# HC32F460PCTB register map
File version: 1.0
CPU: CM4 r0p1, little endian, MPU, FPU, 4 interrupt priority bits
Registers are 32-bit, read-write, reset 0x0 unless marked. A register's access mark holds for its fields unless they carry their own. Offsets are from the block's base; [hi:lo] are bit positions; {n}, {i} and the like mark numbered series.

## AES
Base 0x40008000
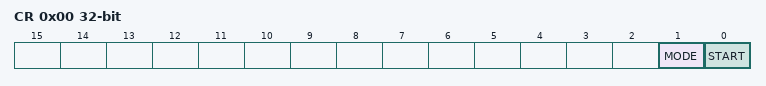
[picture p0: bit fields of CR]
0x00 CR
  [1] MODE, [0] START
{0x10+4i} DR{i} (i=0..3)
{0x20+4i} KR{i} (i=0..3)

## AOS
Base 0x40010800
0x00 INTSFTTRG wo
  [0] STRG
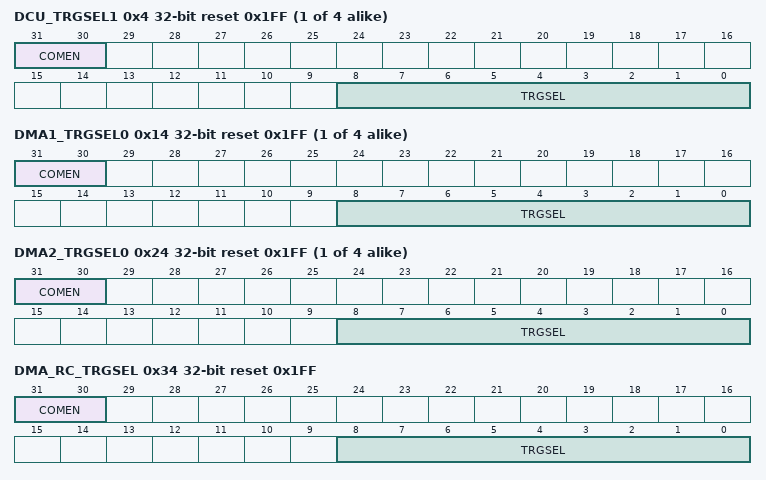
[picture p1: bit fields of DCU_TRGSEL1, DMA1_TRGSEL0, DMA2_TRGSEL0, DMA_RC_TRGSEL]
{0x0+4i} DCU_TRGSEL{i} reset 0x1FF (i=1..4)
  [31:30] COMEN, [8:0] TRGSEL
{0x14+4i} DMA1_TRGSEL{i} reset 0x1FF (i=0..3)
  [31:30] COMEN, [8:0] TRGSEL
{0x24+4i} DMA2_TRGSEL{i} reset 0x1FF (i=0..3)
  [31:30] COMEN, [8:0] TRGSEL
0x34 DMA_RC_TRGSEL reset 0x1FF
  [31:30] COMEN, [8:0] TRGSEL
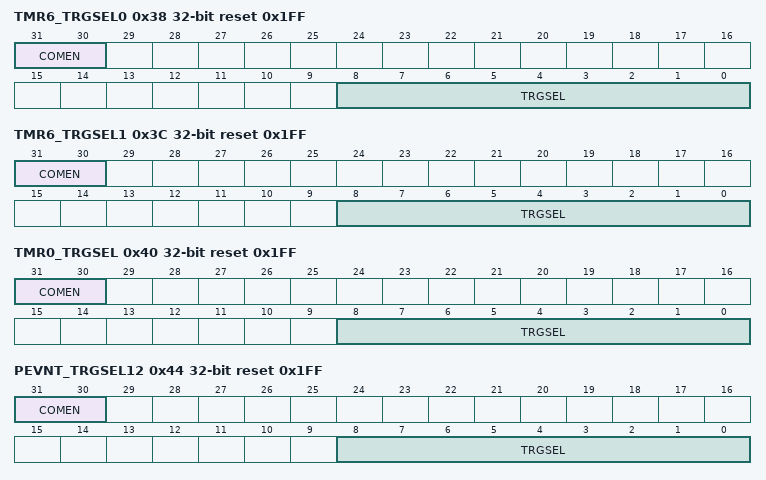
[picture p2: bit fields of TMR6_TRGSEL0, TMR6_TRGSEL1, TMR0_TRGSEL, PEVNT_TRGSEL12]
0x38 TMR6_TRGSEL0 reset 0x1FF
  [31:30] COMEN, [8:0] TRGSEL
0x3C TMR6_TRGSEL1 reset 0x1FF
  [31:30] COMEN, [8:0] TRGSEL
0x40 TMR0_TRGSEL reset 0x1FF
  [31:30] COMEN, [8:0] TRGSEL
0x44 PEVNT_TRGSEL12 reset 0x1FF
  [31:30] COMEN, [8:0] TRGSEL
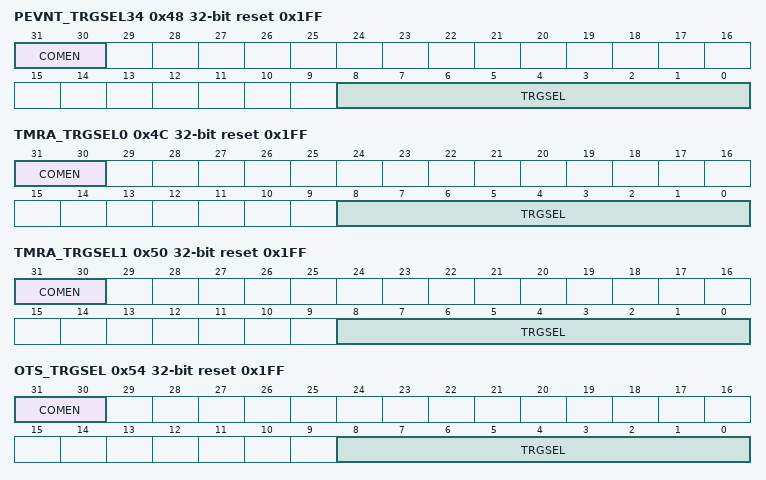
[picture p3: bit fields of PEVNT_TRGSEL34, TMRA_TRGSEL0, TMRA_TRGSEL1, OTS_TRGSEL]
0x48 PEVNT_TRGSEL34 reset 0x1FF
  [31:30] COMEN, [8:0] TRGSEL
0x4C TMRA_TRGSEL0 reset 0x1FF
  [31:30] COMEN, [8:0] TRGSEL
0x50 TMRA_TRGSEL1 reset 0x1FF
  [31:30] COMEN, [8:0] TRGSEL
0x54 OTS_TRGSEL reset 0x1FF
  [31:30] COMEN, [8:0] TRGSEL
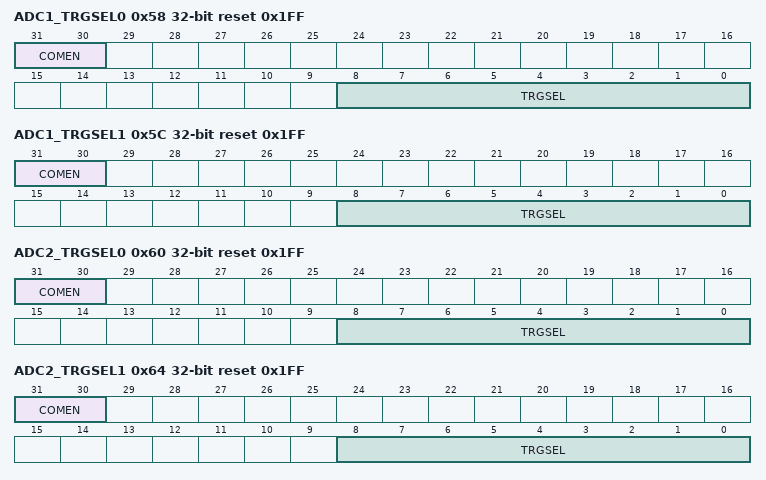
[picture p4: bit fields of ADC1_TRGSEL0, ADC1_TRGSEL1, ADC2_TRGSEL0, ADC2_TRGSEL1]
0x58 ADC1_TRGSEL0 reset 0x1FF
  [31:30] COMEN, [8:0] TRGSEL
0x5C ADC1_TRGSEL1 reset 0x1FF
  [31:30] COMEN, [8:0] TRGSEL
0x60 ADC2_TRGSEL0 reset 0x1FF
  [31:30] COMEN, [8:0] TRGSEL
0x64 ADC2_TRGSEL1 reset 0x1FF
  [31:30] COMEN, [8:0] TRGSEL
0x68 COMTRG1 reset 0x1FF
  [8:0] COMTRG
0x6C COMTRG2 reset 0x1FF
  [8:0] COMTRG
{0xE4+0x1C*i} PEVNTDIRR{i} (i=1..4)
  [15:0] PDIR
{0xE8+0x1C*i} PEVNTIDR{i} ro (i=1..4)
  [15:0] PIN
{0xEC+0x1C*i} PEVNTODR{i} (i=1..4)
  [15:0] POUT
{0xF0+0x1C*i} PEVNTORR{i} (i=1..4)
  [15:0] POR
{0xF4+0x1C*i} PEVNTOSR{i} (i=1..4)
  [15:0] POS
{0xF8+0x1C*i} PEVNTRISR{i} (i=1..4)
  [15:0] RIS
{0xFC+0x1C*i} PEVNTFALR{i} (i=1..4)
  [15:0] FAL
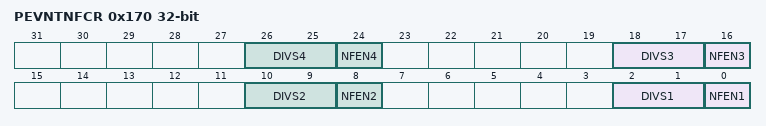
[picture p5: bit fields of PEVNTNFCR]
0x170 PEVNTNFCR
  [8n-6:8n-7] DIVS{n} (n=1..4), [8n-8] NFEN{n} (n=1..4)

## CAN
Base 0x40070400
0x00 RBUF ro
0x50 TBUF
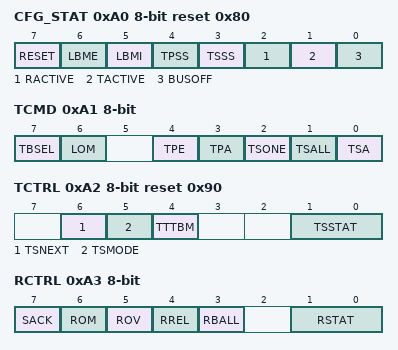
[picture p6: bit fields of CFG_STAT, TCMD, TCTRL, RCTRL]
0xA0 CFG_STAT 8-bit reset 0x80
  [7] RESET, [6] LBME, [5] LBMI, [4] TPSS, [3] TSSS, [2] RACTIVE ro, [1] TACTIVE ro, [0] BUSOFF
0xA1 TCMD 8-bit
  [7] TBSEL, [6] LOM, [4] TPE, [3] TPA, [2] TSONE, [1] TSALL, [0] TSA
0xA2 TCTRL 8-bit reset 0x90
  [6] TSNEXT, [5] TSMODE, [4] TTTBM, [1:0] TSSTAT ro
0xA3 RCTRL 8-bit
  [7] SACK, [6] ROM, [5] ROV ro, [4] RREL, [3] RBALL, [1:0] RSTAT ro
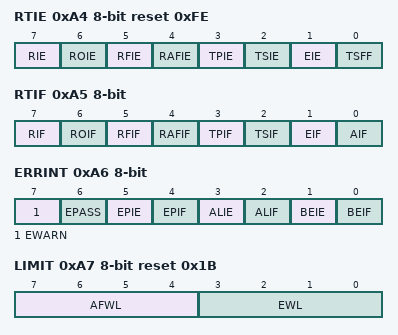
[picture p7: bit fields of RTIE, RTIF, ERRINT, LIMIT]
0xA4 RTIE 8-bit reset 0xFE
  [7] RIE, [6] ROIE, [5] RFIE, [4] RAFIE, [3] TPIE, [2] TSIE, [1] EIE, [0] TSFF ro
0xA5 RTIF 8-bit
  [7] RIF, [6] ROIF, [5] RFIF, [4] RAFIF, [3] TPIF, [2] TSIF, [1] EIF, [0] AIF
0xA6 ERRINT 8-bit
  [7] EWARN ro, [6] EPASS ro, [5] EPIE, [4] EPIF, [3] ALIE, [2] ALIF, [1] BEIE, [0] BEIF
0xA7 LIMIT 8-bit reset 0x1B
  [7:4] AFWL, [3:0] EWL
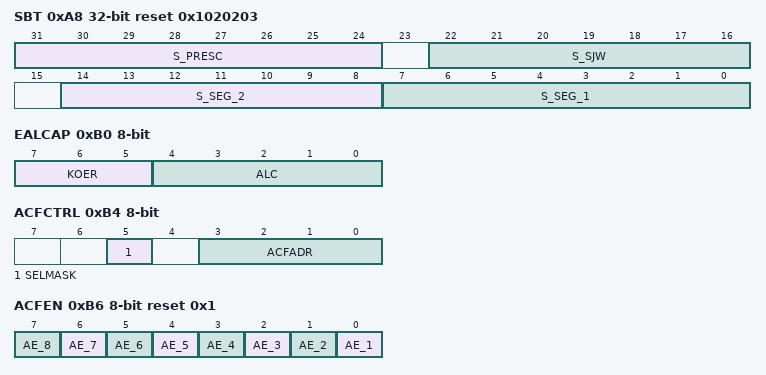
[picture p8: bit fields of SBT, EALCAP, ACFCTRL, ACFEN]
0xA8 SBT reset 0x1020203
  [31:24] S_PRESC, [22:16] S_SJW, [14:8] S_SEG_2, [7:0] S_SEG_1
0xB0 EALCAP 8-bit ro
  [7:5] KOER, [4:0] ALC
0xB2 RECNT 8-bit
0xB3 TECNT 8-bit
0xB4 ACFCTRL 8-bit
  [5] SELMASK, [3:0] ACFADR
0xB6 ACFEN 8-bit reset 0x1
  [n-1] AE_{n} (n=1..8)
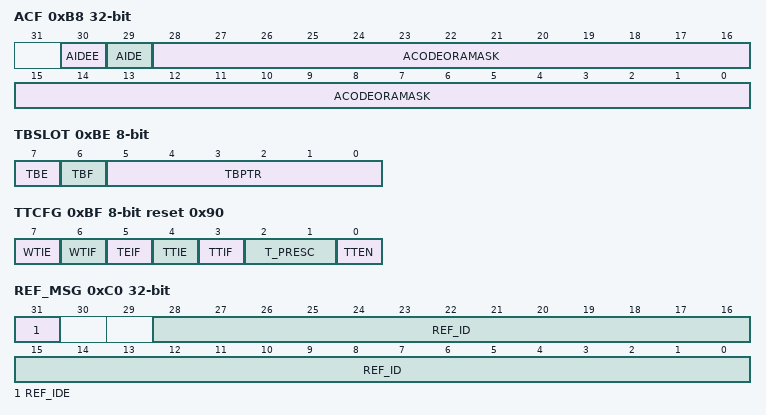
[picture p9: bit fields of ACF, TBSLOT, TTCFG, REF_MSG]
0xB8 ACF
  [30] AIDEE, [29] AIDE, [28:0] ACODEORAMASK
0xBE TBSLOT 8-bit
  [7] TBE, [6] TBF, [5:0] TBPTR
0xBF TTCFG 8-bit reset 0x90
  [7] WTIE, [6] WTIF, [5] TEIF, [4] TTIE, [3] TTIF, [2:1] T_PRESC, [0] TTEN
0xC0 REF_MSG
  [31] REF_IDE, [28:0] REF_ID
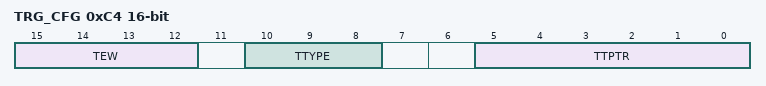
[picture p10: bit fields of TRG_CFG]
0xC4 TRG_CFG 16-bit
  [15:12] TEW, [10:8] TTYPE, [5:0] TTPTR
0xC6 TT_TRIG 16-bit
0xC8 TT_WTRIG 16-bit reset 0xFFFF

## CMP1 — desc CMP
Base 0x4004A000
Same registers: CMP2 0x4004A010, CMP3 0x4004A020
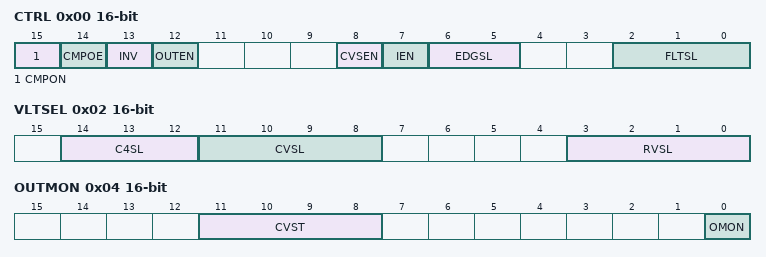
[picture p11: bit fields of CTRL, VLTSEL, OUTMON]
0x00 CTRL 16-bit
  [15] CMPON, [14] CMPOE, [13] INV, [12] OUTEN, [8] CVSEN, [7] IEN, [6:5] EDGSL, [2:0] FLTSL
0x02 VLTSEL 16-bit
  [14:12] C4SL, [11:8] CVSL, [3:0] RVSL
0x04 OUTMON 16-bit ro
  [11:8] CVST, [0] OMON
0x06 CVSSTB 16-bit reset 0x5
  [3:0] STB
0x08 CVSPRD 16-bit reset 0xF
  [7:0] PRD

## CMP_COMMON
Base 0x4004A000; alternate view of CMP1
0x100 DADR1 16-bit
  [7:0] DATA
0x102 DADR2 16-bit
  [7:0] DATA
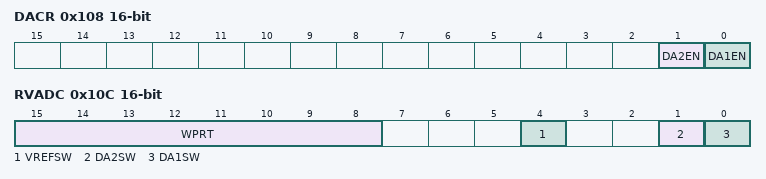
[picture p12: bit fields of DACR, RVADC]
0x108 DACR 16-bit
  [1] DA2EN, [0] DA1EN
0x10C RVADC 16-bit
  [15:8] WPRT, [4] VREFSW, [1] DA2SW, [0] DA1SW
